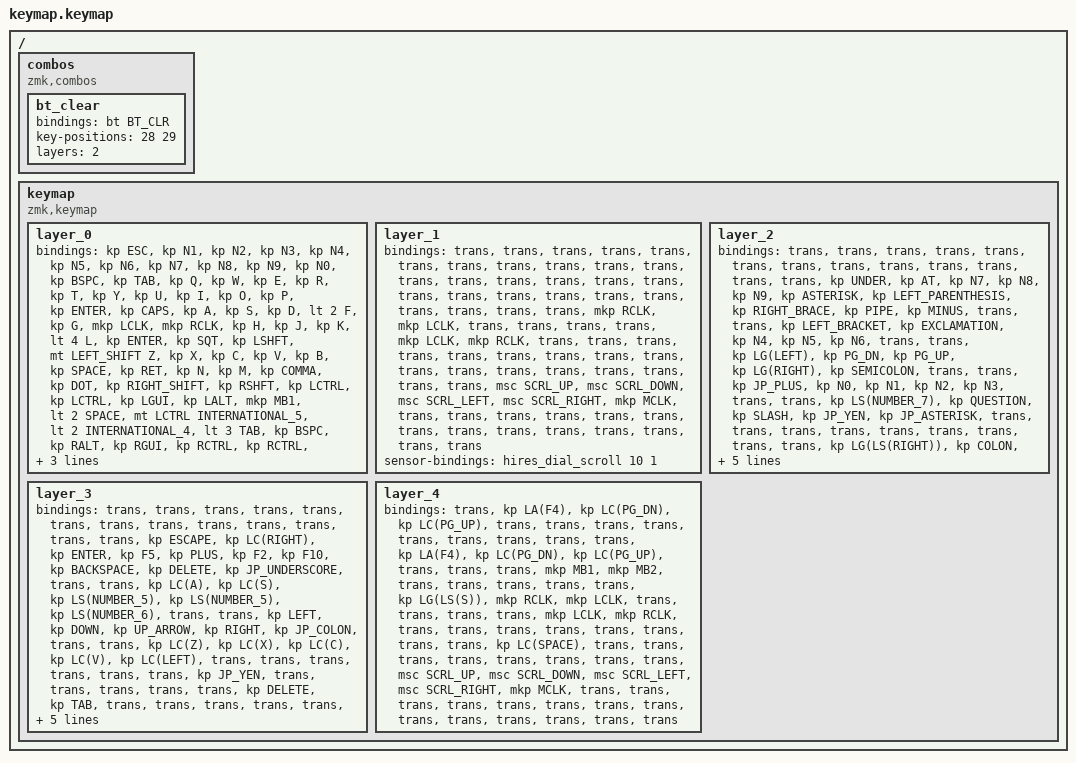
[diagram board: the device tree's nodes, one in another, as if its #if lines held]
#include <behaviors.dtsi>
#include <dt-bindings/zmk/bt.h>
#include <dt-bindings/zmk/keys.h>
#include <dt-bindings/zmk/outputs.h>
#include <dt-bindings/zmk/pointing.h>

#define JP_DQUOTE       AT                // "
#define JP_AMPERSAND    CARET             // &
#define JP_QUOTE        AMPERSAND         // '
#define JP_EQUAL        UNDER             // =
#define JP_CARET        EQUAL             // ^
#define JP_YEN          0x89              // ¥
#define JP_PLUS         COLON             // +
#define JP_TILDE        PLUS              // ~
#define JP_PIPE         LS(0x89)          // |
#define JP_AT           LEFT_BRACKET      // @
#define JP_COLON        SINGLE_QUOTE      // :
#define JP_ASTERISK     DOUBLE_QUOTES     // *
#define JP_BACKQUOTE    LEFT_BRACE        // `
#define JP_UNDERSCORE   LS(0x87)          // _
#define JP_LBRACKET     RIGHT_BRACKET     // [
#define JP_RBRACKET     BACKSLASH         // ]
#define JP_LPAREN       ASTERISK          // (
#define JP_RPAREN       LEFT_PARENTHESIS  // )
#define JP_LBRACE       RIGHT_BRACE       // {
#define JP_RBRACE       PIPE              // }

#if defined(TORABO_TSUKI_LP_INPUT_HIRES_DIAL)
#include <behaviors/hires_dial.dtsi>
#endif

/ {
    combos {
        compatible = "zmk,combos";

        bt_clear {
            bindings = <&bt BT_CLR>;
            key-positions = <28 29>;
            layers = <2>;
        };
    };

    keymap {
        compatible = "zmk,keymap";

        layer_0 {
            bindings = <
&kp ESC    &kp N1     &kp N2    &kp N3    &kp N4    &kp N5                                                         &kp N6       &kp N7    &kp N8     &kp N9    &kp N0                &kp BSPC
&kp TAB    &kp Q      &kp W     &kp E     &kp R     &kp T                                                          &kp Y        &kp U     &kp I      &kp O     &kp P                 &kp ENTER
&kp CAPS   &kp A      &kp S     &kp D     &lt 2 F      &kp G        &mkp LCLK                  &mkp RCLK              &kp H        &kp J     &kp K      &lt 4 L     &kp ENTER              &kp SQT
&kp LSHFT  &mt LEFT_SHIFT Z      &kp X     &kp C     &kp V     &kp B        &kp SPACE                  &kp RET                &kp N        &kp M     &kp COMMA  &kp DOT   &kp RIGHT_SHIFT  &kp RSHFT
&kp LCTRL  &kp LCTRL  &kp LGUI  &kp LALT  &mkp MB1  &lt 2 SPACE  &mt LCTRL INTERNATIONAL_5  &lt 2 INTERNATIONAL_4  &lt 3 TAB  &kp BSPC  &kp RALT   &kp RGUI  &kp RCTRL             &kp RCTRL
#if defined(TORABO_TSUKI_LP_KSCAN_4_DIRECTION_SWITCH)
&msc SCRL_UP &msc SCRL_DOWN &msc SCRL_LEFT &msc SCRL_RIGHT &mkp MCLK
#elif defined(TORABO_TSUKI_LP_INPUT_HIRES_DIAL)
&mkp MCLK
#endif
            >;
        };

        layer_1 {
            bindings = <
&trans  &trans  &trans  &trans     &trans     &trans                  &trans  &trans     &trans     &trans  &trans  &trans
&trans  &trans  &trans  &trans     &trans     &trans                  &trans  &trans     &trans     &trans  &trans  &trans
&trans  &trans  &trans  &mkp RCLK  &mkp LCLK  &trans  &trans  &trans  &trans  &mkp LCLK  &mkp RCLK  &trans  &trans  &trans
&trans  &trans  &trans  &trans     &trans     &trans  &trans  &trans  &trans  &trans     &trans     &trans  &trans  &trans
#if defined(TORABO_TSUKI_LP_KSCAN_4_DIRECTION_SWITCH)
&msc SCRL_UP &msc SCRL_DOWN &msc SCRL_LEFT &msc SCRL_RIGHT &mkp MCLK
#elif defined(TORABO_TSUKI_LP_INPUT_HIRES_DIAL)
&mkp MCLK
#endif
&trans  &trans  &trans  &trans     &trans     &trans  &trans  &trans  &trans  &trans     &trans     &trans  &trans  &trans
            >;
        };

        layer_2 {
            bindings = <
&trans  &trans            &trans            &trans      &trans      &trans                      &trans          &trans         &trans            &trans             &trans         &trans
&trans  &kp UNDER   &kp AT  &kp N7      &kp N8      &kp N9                  &kp ASTERISK       &kp LEFT_PARENTHESIS  &kp RIGHT_BRACE     &kp PIPE  &kp MINUS     &trans
&trans  &kp LEFT_BRACKET      &kp EXCLAMATION            &kp N4      &kp N5      &kp N6      &trans  &trans  &kp LG(LEFT)  &kp PG_DN      &kp PG_UP         &kp LG(RIGHT)  &kp SEMICOLON      &trans
&trans  &kp JP_PLUS            &kp N0            &kp N1      &kp N2      &kp N3      &trans  &trans  &kp LS(NUMBER_7)    &kp QUESTION   &kp SLASH         &kp JP_YEN     &kp JP_ASTERISK  &trans
&trans  &trans            &trans            &trans      &trans      &trans      &trans  &trans  &kp LG(LS(RIGHT))   &kp COLON      &kp LG(UP_ARROW)  &kp BACKSLASH  &kp DOLLAR         &trans
#if defined(TORABO_TSUKI_LP_KSCAN_4_DIRECTION_SWITCH)
&msc SCRL_UP &msc SCRL_DOWN &msc SCRL_LEFT &msc SCRL_RIGHT &mkp MCLK
#elif defined(TORABO_TSUKI_LP_INPUT_HIRES_DIAL)
&kp C_MUTE
#endif
            >;
        };

        layer_3 {
            bindings = <
&trans  &trans   &trans   &trans        &trans        &trans                      &trans            &trans     &trans         &trans     &trans      &trans
&trans  &kp ESCAPE  &kp LC(RIGHT)  &kp ENTER    &kp F5       &kp PLUS                      &kp F2            &kp F10            &kp BACKSPACE   &kp DELETE       &kp JP_UNDERSCORE  &trans
&trans  &kp LC(A)   &kp LC(S)      &kp LS(NUMBER_5)  &kp LS(NUMBER_5)  &kp LS(NUMBER_6)     &trans  &trans  &kp LEFT          &kp DOWN   &kp UP_ARROW   &kp RIGHT  &kp JP_COLON     &trans
&trans  &kp LC(Z)   &kp LC(X)      &kp LC(C)    &kp LC(V)    &kp LC(LEFT)  &trans  &trans  &trans  &trans  &trans  &trans  &kp JP_YEN    &trans
&trans  &trans   &trans   &trans        &kp DELETE    &kp TAB     &trans  &trans  &trans            &trans     &trans         &trans     &kp JP_PIPE      &trans
#if defined(TORABO_TSUKI_LP_KSCAN_4_DIRECTION_SWITCH)
&msc SCRL_UP &msc SCRL_DOWN &msc SCRL_LEFT &msc SCRL_RIGHT &mkp MCLK
#elif defined(TORABO_TSUKI_LP_INPUT_HIRES_DIAL)
&hires_dial_radial_controller_button
#endif
            >;
        };
        layer_4 {
            bindings = <
&trans  &kp LA(F4)  &kp LC(PG_DN)  &kp LC(PG_UP)     &trans     &trans                  &trans  &trans     &trans     &trans  &trans  &trans
&trans  &kp LA(F4)  &kp LC(PG_DN)  &kp LC(PG_UP)     &trans     &trans                  &trans  &mkp MB1    &mkp MB2     &trans  &trans  &trans
&trans  &trans  &kp LG(LS(S))  &mkp RCLK  &mkp LCLK  &trans  &trans  &trans  &trans  &mkp LCLK  &mkp RCLK  &trans  &trans  &trans
&trans  &trans  &trans  &trans     &trans     &kp LC(SPACE)  &trans  &trans  &trans  &trans     &trans     &trans  &trans  &trans
#if defined(TORABO_TSUKI_LP_KSCAN_4_DIRECTION_SWITCH)
&msc SCRL_UP &msc SCRL_DOWN &msc SCRL_LEFT &msc SCRL_RIGHT &mkp MCLK
#elif defined(TORABO_TSUKI_LP_INPUT_HIRES_DIAL)
&mkp MCLK
#endif
&trans  &trans  &trans  &trans     &trans     &trans  &trans  &trans  &trans  &trans     &trans     &trans  &trans  &trans
            >;
        };
    };
};

#if defined(TORABO_TSUKI_LP_INPUT_HIRES_DIAL)
&{/keymap/layer_0} {
    sensor-bindings = <&hires_dial_scroll 1 1>;
};

&{/keymap/layer_1} {
    sensor-bindings = <&hires_dial_scroll 10 1>;
};

&{/keymap/layer_2} {
    sensor-bindings = <&hires_dial_encoder C_VOL_UP C_VOL_DN>;
};

&{/keymap/layer_3} {
    /* Quarter-speed Radial Controller motion: output/input = 1/4. */
    sensor-bindings = <&hires_dial_radial_controller 4 1>;
};
#endif
